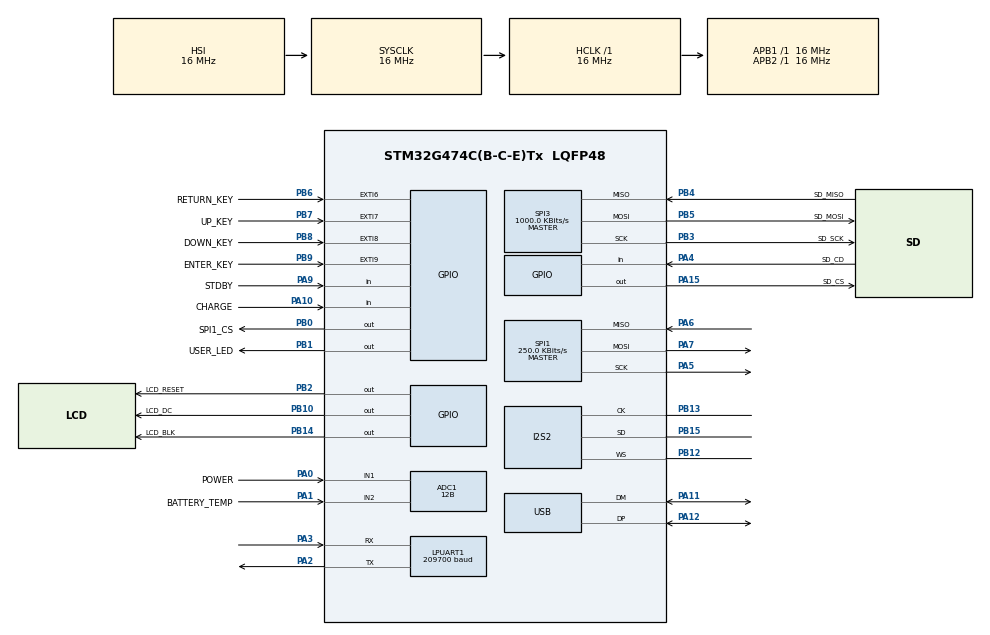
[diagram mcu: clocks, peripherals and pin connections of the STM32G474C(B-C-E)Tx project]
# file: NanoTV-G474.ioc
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ADC1.Channel-0\#ChannelRegularConversion=ADC_CHANNEL_1
ADC1.Channel-IN1=ADC_CHANNEL_1
ADC1.Channel-IN2=ADC_CHANNEL_2
ADC1.ClockPrescaler=ADC_CLOCK_SYNC_PCLK_DIV4
ADC1.ContinuousConvMode=DISABLE
ADC1.DMAContinuousRequests=DISABLE
ADC1.DataAlign=ADC_DATAALIGN_RIGHT
ADC1.DiscontinuousConvMode=DISABLE
ADC1.EOCSelection=ADC_EOC_SINGLE_CONV
ADC1.EnableAnalogWatchDog1=false
ADC1.EnableAnalogWatchDog2=false
ADC1.EnableAnalogWatchDog3=false
ADC1.EnableInjectedConversion=DISABLE
ADC1.EnableRegularConversion=ENABLE
ADC1.ExternalTrigConv=ADC_SOFTWARE_START
ADC1.ExternalTrigConvEdge=ADC_EXTERNALTRIGCONVEDGE_NONE
ADC1.GainCompensation=0
ADC1.LowPowerAutoWait=DISABLE
ADC1.Mode=ADC_MODE_INDEPENDENT
ADC1.NbrOfConversion=1
ADC1.OffsetNumber-0\#ChannelRegularConversion=ADC_OFFSET_NONE
ADC1.Overrun=ADC_OVR_DATA_PRESERVED
ADC1.OversamplingMode=DISABLE
ADC1.Rank-0\#ChannelRegularConversion=1
ADC1.Resolution=ADC_RESOLUTION_12B
ADC1.SamplingTime-0\#ChannelRegularConversion=ADC_SAMPLETIME_2CYCLES_5
ADC1.ScanConvMode=ADC_SCAN_DISABLE
ADC1.master=1
Dma.LPUART1_RX.0.Direction=DMA_PERIPH_TO_MEMORY
Dma.LPUART1_RX.0.EventEnable=DISABLE
Dma.LPUART1_RX.0.Instance=DMA1_Channel1
Dma.LPUART1_RX.0.MemDataAlignment=DMA_MDATAALIGN_BYTE
Dma.LPUART1_RX.0.MemInc=DMA_MINC_ENABLE
Dma.LPUART1_RX.0.Mode=DMA_NORMAL
Dma.LPUART1_RX.0.PeriphDataAlignment=DMA_PDATAALIGN_BYTE
Dma.LPUART1_RX.0.PeriphInc=DMA_PINC_DISABLE
Dma.LPUART1_RX.0.Polarity=HAL_DMAMUX_REQ_GEN_RISING
Dma.LPUART1_RX.0.Priority=DMA_PRIORITY_LOW
Dma.LPUART1_RX.0.RequestNumber=1
Dma.LPUART1_RX.0.SignalID=NONE
Dma.LPUART1_RX.0.SyncEnable=DISABLE
Dma.LPUART1_RX.0.SyncPolarity=HAL_DMAMUX_SYNC_NO_EVENT
Dma.LPUART1_RX.0.SyncRequestNumber=1
Dma.LPUART1_RX.0.SyncSignalID=NONE
Dma.Request0=LPUART1_RX
Dma.Request1=SPI1_TX
Dma.Request2=SPI3_RX
Dma.Request3=SPI3_TX
Dma.Request4=SPI2_TX
Dma.SPI1_TX.1.Direction=DMA_MEMORY_TO_PERIPH
Dma.SPI1_TX.1.EventEnable=DISABLE
Dma.SPI1_TX.1.Instance=DMA1_Channel2
Dma.SPI1_TX.1.MemDataAlignment=DMA_MDATAALIGN_BYTE
Dma.SPI1_TX.1.MemInc=DMA_MINC_ENABLE
Dma.SPI1_TX.1.Mode=DMA_NORMAL
Dma.SPI1_TX.1.PeriphDataAlignment=DMA_PDATAALIGN_BYTE
Dma.SPI1_TX.1.PeriphInc=DMA_PINC_DISABLE
Dma.SPI1_TX.1.Polarity=HAL_DMAMUX_REQ_GEN_RISING
Dma.SPI1_TX.1.Priority=DMA_PRIORITY_LOW
Dma.SPI1_TX.1.RequestNumber=1
Dma.SPI1_TX.1.SignalID=NONE
Dma.SPI1_TX.1.SyncEnable=DISABLE
Dma.SPI1_TX.1.SyncPolarity=HAL_DMAMUX_SYNC_NO_EVENT
Dma.SPI1_TX.1.SyncRequestNumber=1
Dma.SPI1_TX.1.SyncSignalID=NONE
Dma.SPI2_TX.4.Direction=DMA_MEMORY_TO_PERIPH
Dma.SPI2_TX.4.EventEnable=DISABLE
Dma.SPI2_TX.4.Instance=DMA1_Channel3
Dma.SPI2_TX.4.MemDataAlignment=DMA_MDATAALIGN_BYTE
Dma.SPI2_TX.4.MemInc=DMA_MINC_ENABLE
Dma.SPI2_TX.4.Mode=DMA_NORMAL
Dma.SPI2_TX.4.PeriphDataAlignment=DMA_PDATAALIGN_BYTE
Dma.SPI2_TX.4.PeriphInc=DMA_PINC_DISABLE
Dma.SPI2_TX.4.Polarity=HAL_DMAMUX_REQ_GEN_RISING
Dma.SPI2_TX.4.Priority=DMA_PRIORITY_LOW
Dma.SPI2_TX.4.RequestNumber=1
Dma.SPI2_TX.4.SignalID=NONE
Dma.SPI2_TX.4.SyncEnable=DISABLE
Dma.SPI2_TX.4.SyncPolarity=HAL_DMAMUX_SYNC_NO_EVENT
Dma.SPI2_TX.4.SyncRequestNumber=1
Dma.SPI2_TX.4.SyncSignalID=NONE
Dma.SPI3_RX.2.Direction=DMA_PERIPH_TO_MEMORY
Dma.SPI3_RX.2.EventEnable=DISABLE
Dma.SPI3_RX.2.Instance=DMA1_Channel4
Dma.SPI3_RX.2.MemDataAlignment=DMA_MDATAALIGN_BYTE
Dma.SPI3_RX.2.MemInc=DMA_MINC_ENABLE
Dma.SPI3_RX.2.Mode=DMA_NORMAL
Dma.SPI3_RX.2.PeriphDataAlignment=DMA_PDATAALIGN_BYTE
Dma.SPI3_RX.2.PeriphInc=DMA_PINC_DISABLE
Dma.SPI3_RX.2.Polarity=HAL_DMAMUX_REQ_GEN_RISING
Dma.SPI3_RX.2.Priority=DMA_PRIORITY_LOW
Dma.SPI3_RX.2.RequestNumber=1
Dma.SPI3_RX.2.SignalID=NONE
Dma.SPI3_RX.2.SyncEnable=DISABLE
Dma.SPI3_RX.2.SyncPolarity=HAL_DMAMUX_SYNC_NO_EVENT
Dma.SPI3_RX.2.SyncRequestNumber=1
Dma.SPI3_RX.2.SyncSignalID=NONE
Dma.SPI3_TX.3.Direction=DMA_MEMORY_TO_PERIPH
Dma.SPI3_TX.3.EventEnable=DISABLE
Dma.SPI3_TX.3.Instance=DMA1_Channel5
Dma.SPI3_TX.3.MemDataAlignment=DMA_MDATAALIGN_BYTE
Dma.SPI3_TX.3.MemInc=DMA_MINC_ENABLE
Dma.SPI3_TX.3.Mode=DMA_NORMAL
Dma.SPI3_TX.3.PeriphDataAlignment=DMA_PDATAALIGN_BYTE
Dma.SPI3_TX.3.PeriphInc=DMA_PINC_DISABLE
Dma.SPI3_TX.3.Polarity=HAL_DMAMUX_REQ_GEN_RISING
Dma.SPI3_TX.3.Priority=DMA_PRIORITY_LOW
Dma.SPI3_TX.3.RequestNumber=1
Dma.SPI3_TX.3.SignalID=NONE
Dma.SPI3_TX.3.SyncEnable=DISABLE
Dma.SPI3_TX.3.SyncPolarity=HAL_DMAMUX_SYNC_NO_EVENT
Dma.SPI3_TX.3.SyncRequestNumber=1
Dma.SPI3_TX.3.SyncSignalID=NONE
I2S2.AudioFreq=AudioFreqCustomValue
I2S2.AudioFreqCustom=68000
I2S2.CPOL=I2S_CPOL_LOW
I2S2.DataFormat=I2S_DATAFORMAT_16B
I2S2.ErrorAudioFreq=5.04 %
I2S2.FullDuplexMode=I2S_FULLDUPLEXMODE_DISABLE
I2S2.Instance=SPI$Index
I2S2.Mode=I2S_MODE_MASTER_TX
I2S2.RealAudioFreq=71.428 KHz
I2S2.Standard=I2S_STANDARD_PHILIPS
I2S2.VirtualMode=I2S_MODE_MASTER
LPUART1.BaudRate=209700
LPUART1.ClockPrescaler=UART_PRESCALER_DIV1
LPUART1.DMADisableonRxErrorParam=UART_ADVFEATURE_DMA_ENABLEONRXERROR
LPUART1.DataInvertParam=UART_ADVFEATURE_DATAINV_DISABLE
LPUART1.FIFOMode=UART_FIFOMODE_DISABLE
LPUART1.MSBFirstParam=UART_ADVFEATURE_MSBFIRST_DISABLE
LPUART1.Mode=UART_MODE_TX_RX
LPUART1.OneBitSampling=UART_ONE_BIT_SAMPLE_DISABLE
LPUART1.OverrunDisableParam=UART_ADVFEATURE_OVERRUN_ENABLE
LPUART1.Parity=UART_PARITY_NONE
LPUART1.RXFIFOThreshold=UART_RXFIFO_THRESHOLD_1_8
LPUART1.RxPinLevelInvertParam=UART_ADVFEATURE_RXINV_DISABLE
LPUART1.StopBits=UART_STOPBITS_1
LPUART1.SwapParam=UART_ADVFEATURE_SWAP_DISABLE
LPUART1.TXFIFOThreshold=UART_TXFIFO_THRESHOLD_1_8
LPUART1.TxPinLevelInvertParam=UART_ADVFEATURE_TXINV_DISABLE
LPUART1.WordLength=UART_WORDLENGTH_8B
Mcu.Family=STM32G4
Mcu.Name=STM32G474C(B-C-E)Tx
Mcu.Package=LQFP48
NVIC.EXTI9_5_IRQn=true\:0\:0\:false\:false\:true\:true\:true\:true
NVIC.LPUART1_IRQn=true\:0\:0\:false\:false\:true\:true\:true\:true
NVIC.PriorityGroup=NVIC_PRIORITYGROUP_4
NVIC.TIM7_DAC_IRQn=true\:1\:0\:true\:false\:true\:true\:true\:true
PA0.GPIO_Label=POWER
PA0.Mode=IN1-Single-Ended
PA0.Signal=ADC1_IN1
PA1.GPIO_Label=BATTERY_TEMP
PA1.Mode=IN2-Single-Ended
PA1.Signal=ADC1_IN2
PA10.GPIO_Label=CHARGE
PA10.Signal=GPIO_Input
PA11.Mode=Device
PA11.Signal=USB_DM
PA12.Mode=Device
PA12.Signal=USB_DP
PA13.Mode=Serial_Wire
PA13.Signal=SYS_JTMS-SWDIO
PA14.Mode=Serial_Wire
PA14.Signal=SYS_JTCK-SWCLK
PA15.GPIO_Label=SD_CS
PA15.Signal=GPIO_Output
PA2.Mode=Asynchronous
PA2.Signal=LPUART1_TX
PA3.Mode=Asynchronous
PA3.Signal=LPUART1_RX
PA4.GPIO_Label=SD_CD
PA4.Signal=GPIO_Input
PA5.Mode=Full_Duplex_Master
PA5.Signal=SPI1_SCK
PA6.Mode=Full_Duplex_Master
PA6.Signal=SPI1_MISO
PA7.Mode=Full_Duplex_Master
PA7.Signal=SPI1_MOSI
PA9.GPIO_Label=STDBY
PA9.Signal=GPIO_Input
PB0.GPIO_Label=SPI1_CS
PB0.Signal=GPIO_Output
PB1.GPIO_Label=USER_LED
PB1.Signal=GPIO_Output
PB10.GPIO_Label=LCD_DC
PB10.Signal=GPIO_Output
PB12.Mode=Half_Duplex_Master
PB12.Signal=I2S2_WS
PB13.Mode=Half_Duplex_Master
PB13.Signal=I2S2_CK
PB14.GPIO_Label=LCD_BLK
PB14.Signal=GPIO_Output
PB15.Mode=Half_Duplex_Master
PB15.Signal=I2S2_SD
PB2.GPIO_Label=LCD_RESET
PB2.Signal=GPIO_Output
PB3.GPIO_Label=SD_SCK
PB3.Mode=Full_Duplex_Master
PB3.Signal=SPI3_SCK
PB4.GPIO_Label=SD_MISO
PB4.Mode=Full_Duplex_Master
PB4.Signal=SPI3_MISO
PB5.GPIO_Label=SD_MOSI
PB5.Mode=Full_Duplex_Master
PB5.Signal=SPI3_MOSI
PB6.GPIO_Label=RETURN_KEY
PB6.Signal=GPXTI6
PB7.GPIO_Label=UP_KEY
PB7.Signal=GPXTI7
PB8-BOOT0.GPIO_Label=DOWN_KEY
PB8-BOOT0.Signal=GPXTI8
PB9.GPIO_Label=ENTER_KEY
PB9.Signal=GPXTI9
PC14-OSC32_IN.Mode=LSE-External-Oscillator
PC14-OSC32_IN.Signal=RCC_OSC32_IN
PC15-OSC32_OUT.Mode=LSE-External-Oscillator
PC15-OSC32_OUT.Signal=RCC_OSC32_OUT
ProjectManager.HeapSize=0x200
ProjectManager.StackSize=0x400
ProjectManager.TargetToolchain=MDK-ARM V5.32
RCC.ADC12Freq_Value=16000000
RCC.ADC345Freq_Value=16000000
RCC.AHBFreq_Value=16000000
RCC.APB1Freq_Value=16000000
RCC.APB1TimFreq_Value=16000000
RCC.APB2Freq_Value=16000000
RCC.APB2TimFreq_Value=16000000
RCC.CortexFreq_Value=16000000
RCC.EXTERNAL_CLOCK_VALUE=12288000
RCC.HCLKFreq_Value=16000000
RCC.HSE_VALUE=8000000
RCC.HSI48_VALUE=48000000
RCC.HSI_VALUE=16000000
RCC.PLLN=12
RCC.PLLQ=RCC_PLLQ_DIV4
RCC.SYSCLKFreq_VALUE=16000000
RCC.USBFreq_Value=48000000
RCC.VCOOutputFreq_Value=192000000
RTC.AsynchPrediv=127
RTC.HourFormat=RTC_HOURFORMAT_24
RTC.SynchPrediv=255
SPI1.BaudRatePrescaler=SPI_BAUDRATEPRESCALER_64
SPI1.CLKPhase=SPI_PHASE_1EDGE
SPI1.CLKPolarity=SPI_POLARITY_LOW
SPI1.CRCCalculation=SPI_CRCCALCULATION_DISABLE
SPI1.CalculateBaudRate=250.0 KBits/s
SPI1.DataSize=SPI_DATASIZE_4BIT
SPI1.Direction=SPI_DIRECTION_2LINES
SPI1.FirstBit=SPI_FIRSTBIT_MSB
SPI1.Mode=SPI_MODE_MASTER
SPI1.NSS=SPI_NSS_SOFT
SPI1.NSSPMode=SPI_NSS_PULSE_ENABLE
SPI1.TIMode=SPI_TIMODE_DISABLE
SPI1.VirtualType=VM_MASTER
SPI3.BaudRatePrescaler=SPI_BAUDRATEPRESCALER_16
SPI3.CLKPhase=SPI_PHASE_1EDGE
SPI3.CLKPolarity=SPI_POLARITY_LOW
SPI3.CRCCalculation=SPI_CRCCALCULATION_DISABLE
SPI3.CalculateBaudRate=1000.0 KBits/s
SPI3.DataSize=SPI_DATASIZE_8BIT
SPI3.Direction=SPI_DIRECTION_2LINES
SPI3.FirstBit=SPI_FIRSTBIT_MSB
SPI3.Mode=SPI_MODE_MASTER
SPI3.NSS=SPI_NSS_SOFT
SPI3.NSSPMode=SPI_NSS_PULSE_ENABLE
SPI3.TIMode=SPI_TIMODE_DISABLE
SPI3.VirtualType=VM_MASTER
TIM7.AutoReloadPreload=TIM_AUTORELOAD_PRELOAD_ENABLE
TIM7.CounterMode=TIM_COUNTERMODE_UP
TIM7.Dithering=Disable
TIM7.PeriodNoDither=999
TIM7.Prescaler=169
TIM7.TIM_MasterOutputTrigger=TIM_TRGO_RESET
USB.DeviceSpeed=PCD_SPEED_FULL
USB.Sof_enable=DISABLE
USB.battery_charging_enable=DISABLE
USB.low_power_enable=DISABLE
USB.lpm_enable=DISABLE
USB.phy_itface=PCD_PHY_EMBEDDED
VP_RTC_VS_RTC_Activate.Mode=RTC_Enabled
VP_SYS_VS_DBSignals.Mode=DisableDeadBatterySignals
VP_TIM7_VS_ClockSourceINT.Mode=Enable_Timer
board=custom

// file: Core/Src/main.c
/* USER CODE BEGIN Header */
/**
  ******************************************************************************
  * @file           : main.c
  * @brief          : Main program body
  ******************************************************************************
  * @attention
  *
  * Copyright (c) 2025 STMicroelectronics.
  * All rights reserved.
  *
  * This software is licensed under terms that can be found in the LICENSE file
  * in the root directory of this software component.
  * If no LICENSE file comes with this software, it is provided AS-IS.
  *
  ******************************************************************************
  */
/* USER CODE END Header */
#include "main.h"
#include "adc.h"
#include "dma.h"
#include "i2s.h"
#include "usart.h"
#include "rtc.h"
#include "spi.h"
#include "tim.h"
#include "usb.h"
#include "gpio.h"

/* USER CODE BEGIN Includes */
#include "flag.h"
/* USER CODE END Includes */

void SystemClock_Config(void);

int main(void)
{

  /* MCU Configuration--------------------------------------------------------*/

  /* Reset of all peripherals, Initializes the Flash interface and the Systick. */
  HAL_Init();

  /* Configure the system clock */
  SystemClock_Config();

  /* Initialize all configured peripherals */
  MX_GPIO_Init();
  MX_DMA_Init();
  MX_ADC1_Init();
  MX_I2S2_Init();
  MX_LPUART1_UART_Init();
  MX_SPI1_Init();
  MX_TIM7_Init();
  MX_USB_PCD_Init();
  MX_RTC_Init();
  MX_SPI3_Init();

  /* Infinite loop */
  while (1)
  {

  }
}

void SystemClock_Config(void)
{
  RCC_OscInitTypeDef RCC_OscInitStruct = {0};
  RCC_ClkInitTypeDef RCC_ClkInitStruct = {0};

  /** Configure the main internal regulator output voltage
  */
  HAL_PWREx_ControlVoltageScaling(PWR_REGULATOR_VOLTAGE_SCALE1);

  /** Initializes the RCC Oscillators according to the specified parameters
  * in the RCC_OscInitTypeDef structure.
  */
  RCC_OscInitStruct.OscillatorType = RCC_OSCILLATORTYPE_HSI|RCC_OSCILLATORTYPE_LSI;
  RCC_OscInitStruct.HSIState = RCC_HSI_ON;
  RCC_OscInitStruct.HSICalibrationValue = RCC_HSICALIBRATION_DEFAULT;
  RCC_OscInitStruct.LSIState = RCC_LSI_ON;
  RCC_OscInitStruct.PLL.PLLState = RCC_PLL_ON;
  RCC_OscInitStruct.PLL.PLLSource = RCC_PLLSOURCE_HSI;
  RCC_OscInitStruct.PLL.PLLM = RCC_PLLM_DIV1;
  RCC_OscInitStruct.PLL.PLLN = 12;
  RCC_OscInitStruct.PLL.PLLP = RCC_PLLP_DIV2;
  RCC_OscInitStruct.PLL.PLLQ = RCC_PLLQ_DIV4;
  RCC_OscInitStruct.PLL.PLLR = RCC_PLLR_DIV2;
  if (HAL_RCC_OscConfig(&RCC_OscInitStruct) != HAL_OK)
  {
    Error_Handler();
  }

  /** Initializes the CPU, AHB and APB buses clocks
  */
  RCC_ClkInitStruct.ClockType = RCC_CLOCKTYPE_HCLK|RCC_CLOCKTYPE_SYSCLK
                              |RCC_CLOCKTYPE_PCLK1|RCC_CLOCKTYPE_PCLK2;
  RCC_ClkInitStruct.SYSCLKSource = RCC_SYSCLKSOURCE_HSI;
  RCC_ClkInitStruct.AHBCLKDivider = RCC_SYSCLK_DIV1;
  RCC_ClkInitStruct.APB1CLKDivider = RCC_HCLK_DIV1;
  RCC_ClkInitStruct.APB2CLKDivider = RCC_HCLK_DIV1;

  if (HAL_RCC_ClockConfig(&RCC_ClkInitStruct, FLASH_LATENCY_0) != HAL_OK)
  {
    Error_Handler();
  }
}

void Error_Handler(void)
{
  __disable_irq();
  while (1)
  {
  }
}
